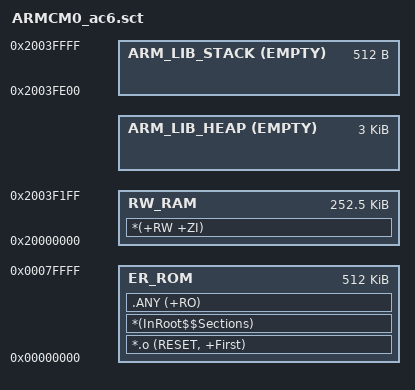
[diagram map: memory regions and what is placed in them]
#! armclang -E --target=arm-arm-none-eabi -mcpu=cortex-m0 -xc

#define __ROM_BASE      0x00000000
#define __ROM_SIZE      0x00080000
#define __RAM_BASE      0x20000000
#define __RAM_SIZE      0x00040000

#define __STACK_SIZE    0x00000200
#define __HEAP_SIZE     0x00000C00
#define __STACK_TOP     (__RAM_BASE + __RAM_SIZE)

LR_ROM __ROM_BASE __ROM_SIZE  {
    ER_ROM __ROM_BASE __ROM_SIZE  {
        *.o (RESET, +First)
        *(InRoot$$Sections)
        .ANY (+RO)
    }

    RW_RAM __RAM_BASE (__RAM_SIZE - __STACK_SIZE - __HEAP_SIZE) {
        *(+RW +ZI)
    }

    #if __HEAP_SIZE > 0
    ARM_LIB_HEAP  (AlignExpr(+0, 8)) EMPTY __HEAP_SIZE {
    }
    #endif

    ARM_LIB_STACK __STACK_TOP EMPTY -__STACK_SIZE {
    }
}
